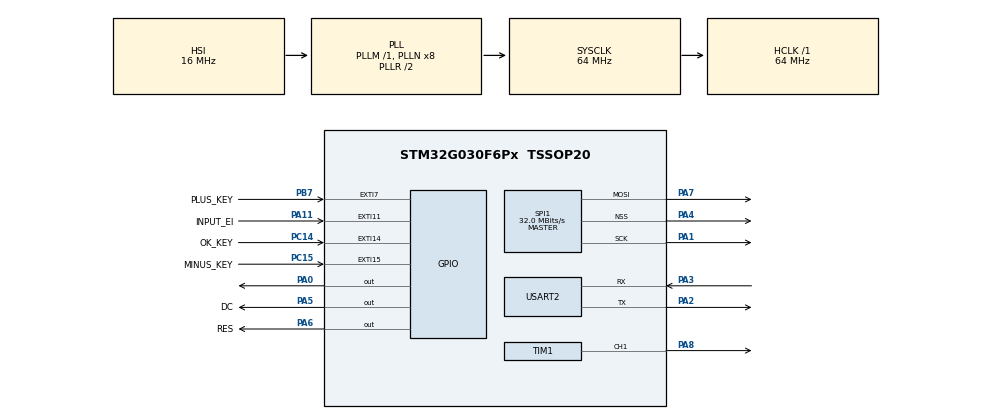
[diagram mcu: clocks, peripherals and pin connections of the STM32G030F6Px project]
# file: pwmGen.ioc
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Dma.Request0=SPI1_TX
Dma.Request1=USART2_TX
Dma.SPI1_TX.0.Direction=DMA_MEMORY_TO_PERIPH
Dma.SPI1_TX.0.EventEnable=DISABLE
Dma.SPI1_TX.0.Instance=DMA1_Channel1
Dma.SPI1_TX.0.MemDataAlignment=DMA_MDATAALIGN_BYTE
Dma.SPI1_TX.0.MemInc=DMA_MINC_ENABLE
Dma.SPI1_TX.0.Mode=DMA_NORMAL
Dma.SPI1_TX.0.PeriphDataAlignment=DMA_PDATAALIGN_BYTE
Dma.SPI1_TX.0.PeriphInc=DMA_PINC_DISABLE
Dma.SPI1_TX.0.Polarity=HAL_DMAMUX_REQ_GEN_RISING
Dma.SPI1_TX.0.Priority=DMA_PRIORITY_VERY_HIGH
Dma.SPI1_TX.0.RequestNumber=1
Dma.SPI1_TX.0.SignalID=NONE
Dma.SPI1_TX.0.SyncEnable=DISABLE
Dma.SPI1_TX.0.SyncPolarity=HAL_DMAMUX_SYNC_NO_EVENT
Dma.SPI1_TX.0.SyncRequestNumber=1
Dma.SPI1_TX.0.SyncSignalID=NONE
Dma.USART2_TX.1.Direction=DMA_MEMORY_TO_PERIPH
Dma.USART2_TX.1.EventEnable=DISABLE
Dma.USART2_TX.1.Instance=DMA1_Channel3
Dma.USART2_TX.1.MemDataAlignment=DMA_MDATAALIGN_BYTE
Dma.USART2_TX.1.MemInc=DMA_MINC_ENABLE
Dma.USART2_TX.1.Mode=DMA_NORMAL
Dma.USART2_TX.1.PeriphDataAlignment=DMA_PDATAALIGN_BYTE
Dma.USART2_TX.1.PeriphInc=DMA_PINC_DISABLE
Dma.USART2_TX.1.Polarity=HAL_DMAMUX_REQ_GEN_RISING
Dma.USART2_TX.1.Priority=DMA_PRIORITY_LOW
Dma.USART2_TX.1.RequestNumber=1
Dma.USART2_TX.1.SignalID=NONE
Dma.USART2_TX.1.SyncEnable=DISABLE
Dma.USART2_TX.1.SyncPolarity=HAL_DMAMUX_SYNC_NO_EVENT
Dma.USART2_TX.1.SyncRequestNumber=1
Dma.USART2_TX.1.SyncSignalID=NONE
FREERTOS.BinarySemaphores01=spiTranBinarySem,Dynamic,NULL;pageBinarySem,Dynamic,NULL;uartSendBinarySem,Dynamic,NULL
FREERTOS.Tasks01=guiTask,0,128,osGuiTask,Default,NULL,Dynamic,NULL,NULL;shellTask,-3,256,osShellTask,Default,NULL,Dynamic,NULL,NULL
FREERTOS.configTOTAL_HEAP_SIZE=3072
Mcu.Family=STM32G0
Mcu.Name=STM32G030F6Px
Mcu.Package=TSSOP20
NVIC.DMA1_Channel1_IRQn=true\:3\:0\:false\:false\:true\:true\:false\:true\:true
NVIC.DMA1_Channel2_3_IRQn=true\:3\:0\:false\:false\:true\:true\:false\:true\:true
NVIC.EXTI4_15_IRQn=true\:3\:0\:false\:false\:true\:true\:true\:true\:true
NVIC.SPI1_IRQn=true\:3\:0\:false\:false\:true\:true\:true\:true\:true
NVIC.TIM17_IRQn=true\:3\:0\:false\:false\:true\:false\:false\:true\:true
NVIC.TimeBase=TIM17_IRQn
NVIC.TimeBaseIP=TIM17
NVIC.USART2_IRQn=true\:3\:0\:false\:false\:true\:true\:true\:true\:true
PA0.Signal=GPIO_Output
PA1.GPIO_Speed=GPIO_SPEED_FREQ_VERY_HIGH
PA1.Mode=TX_Only_Simplex_Unidirect_Master
PA1.Signal=SPI1_SCK
PA11\ [PA9].GPIO_Label=INPUT_EI
PA11\ [PA9].GPIO_ModeDefaultEXTI=GPIO_MODE_IT_RISING_FALLING
PA11\ [PA9].Signal=GPXTI11
PA13.Mode=Serial_Wire
PA13.Signal=SYS_SWDIO
PA14-BOOT0.Mode=Serial_Wire
PA14-BOOT0.Signal=SYS_SWCLK
PA14-BOOT0__PA15.StandardMode=true
PA2.Mode=Asynchronous
PA2.Signal=USART2_TX
PA3.Mode=Asynchronous
PA3.Signal=USART2_RX
PA4.GPIO_Speed=GPIO_SPEED_FREQ_VERY_HIGH
PA4.Mode=NSS_Signal_Hard_Output
PA4.Signal=SPI1_NSS
PA5.GPIO_Label=DC
PA5.Signal=GPIO_Output
PA6.GPIO_Label=RES
PA6.GPIO_Speed=GPIO_SPEED_FREQ_VERY_HIGH
PA6.Signal=GPIO_Output
PA7.GPIO_Speed=GPIO_SPEED_FREQ_VERY_HIGH
PA7.Mode=TX_Only_Simplex_Unidirect_Master
PA7.Signal=SPI1_MOSI
PA8.GPIO_ModeDefaultPP=GPIO_MODE_AF_OD
PA8.GPIO_Speed=GPIO_SPEED_FREQ_VERY_HIGH
PA8.PinState=GPIO_PIN_SET
PA8.Signal=S_TIM1_CH1
PB0__PB1__PB2__PA8.StandardMode=true
PB3__PB4__PB5__PB6.StandardMode=true
PB7.GPIO_Label=PLUS_KEY
PB7.GPIO_ModeDefaultEXTI=GPIO_MODE_IT_RISING_FALLING
PB7.GPIO_PuPd=GPIO_NOPULL
PB7.Signal=GPXTI7
PB7__PB8.StandardMode=true
PC14-OSC32_IN\ (PC14).GPIO_Label=OK_KEY
PC14-OSC32_IN\ (PC14).GPIO_ModeDefaultEXTI=GPIO_MODE_IT_RISING_FALLING
PC14-OSC32_IN\ (PC14).GPIO_PuPd=GPIO_NOPULL
PC14-OSC32_IN\ (PC14).Signal=GPXTI14
PC14-OSC32_IN\ (PC14)__PB9.StandardMode=true
PC15-OSC32_OUT\ (PC15).GPIO_Label=MINUS_KEY
PC15-OSC32_OUT\ (PC15).GPIO_ModeDefaultEXTI=GPIO_MODE_IT_RISING_FALLING
PC15-OSC32_OUT\ (PC15).GPIO_PuPd=GPIO_NOPULL
PC15-OSC32_OUT\ (PC15).Signal=GPXTI15
ProjectManager.HeapSize=0x200
ProjectManager.StackSize=0x400
ProjectManager.TargetToolchain=MDK-ARM V5.32
RCC.ADCFreq_Value=64000000
RCC.AHBFreq_Value=64000000
RCC.CortexFreq_Value=64000000
RCC.EXTERNAL_CLOCK_VALUE=12288000
RCC.HCLKFreq_Value=64000000
RCC.HSE_VALUE=8000000
RCC.HSI_VALUE=16000000
RCC.LSE_VALUE=32768
RCC.SYSCLKFreq_VALUE=64000000
RCC.SYSCLKSource=RCC_SYSCLKSOURCE_PLLCLK
RCC.VCOOutputFreq_Value=128000000
SH.S_TIM1_CH1.0=TIM1_CH1,PWM Generation1 CH1
SPI1.BaudRatePrescaler=SPI_BAUDRATEPRESCALER_2
SPI1.CalculateBaudRate=32.0 MBits/s
SPI1.DataSize=SPI_DATASIZE_8BIT
SPI1.Direction=SPI_DIRECTION_2LINES
SPI1.Mode=SPI_MODE_MASTER
SPI1.VirtualNSS=VM_NSSHARD
SPI1.VirtualType=VM_MASTER
TIM1.Channel-PWM\ Generation1\ CH1=TIM_CHANNEL_1
USART2.VirtualMode-Asynchronous=VM_ASYNC
VP_FREERTOS_VS_CMSIS_V1.Mode=CMSIS_V1
VP_SYS_VS_tim17.Mode=TIM17
VP_TIM1_VS_ClockSourceINT.Mode=Internal
board=custom

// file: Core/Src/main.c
/* USER CODE BEGIN Header */
/**
  ******************************************************************************
  * @file           : main.c
  * @brief          : Main program body
  ******************************************************************************
  * @attention
  *
  * Copyright (c) 2024 STMicroelectronics.
  * All rights reserved.
  *
  * This software is licensed under terms that can be found in the LICENSE file
  * in the root directory of this software component.
  * If no LICENSE file comes with this software, it is provided AS-IS.
  *
  ******************************************************************************
  */
/* USER CODE END Header */
#include "main.h"
#include "cmsis_os.h"
#include "dma.h"
#include "spi.h"
#include "tim.h"
#include "usart.h"
#include "gpio.h"

void SystemClock_Config(void);
void MX_FREERTOS_Init(void);

int main(void)
{

  /* MCU Configuration--------------------------------------------------------*/

  /* Reset of all peripherals, Initializes the Flash interface and the Systick. */
  HAL_Init();

  /* Configure the system clock */
  SystemClock_Config();

  /* Initialize all configured peripherals */
  MX_GPIO_Init();
  MX_DMA_Init();
  MX_SPI1_Init();
  MX_TIM1_Init();
  MX_USART2_UART_Init();

  /* Call init function for freertos objects (in cmsis_os2.c) */
  MX_FREERTOS_Init();

  /* Start scheduler */
  osKernelStart();

  /* We should never get here as control is now taken by the scheduler */

  /* Infinite loop */
  while (1)
  {

  }
}

void SystemClock_Config(void)
{
  RCC_OscInitTypeDef RCC_OscInitStruct = {0};
  RCC_ClkInitTypeDef RCC_ClkInitStruct = {0};

  /** Configure the main internal regulator output voltage
  */
  HAL_PWREx_ControlVoltageScaling(PWR_REGULATOR_VOLTAGE_SCALE1);

  /** Initializes the RCC Oscillators according to the specified parameters
  * in the RCC_OscInitTypeDef structure.
  */
  RCC_OscInitStruct.OscillatorType = RCC_OSCILLATORTYPE_HSI;
  RCC_OscInitStruct.HSIState = RCC_HSI_ON;
  RCC_OscInitStruct.HSIDiv = RCC_HSI_DIV1;
  RCC_OscInitStruct.HSICalibrationValue = RCC_HSICALIBRATION_DEFAULT;
  RCC_OscInitStruct.PLL.PLLState = RCC_PLL_ON;
  RCC_OscInitStruct.PLL.PLLSource = RCC_PLLSOURCE_HSI;
  RCC_OscInitStruct.PLL.PLLM = RCC_PLLM_DIV1;
  RCC_OscInitStruct.PLL.PLLN = 8;
  RCC_OscInitStruct.PLL.PLLP = RCC_PLLP_DIV2;
  RCC_OscInitStruct.PLL.PLLR = RCC_PLLR_DIV2;
  if (HAL_RCC_OscConfig(&RCC_OscInitStruct) != HAL_OK)
  {
    Error_Handler();
  }

  /** Initializes the CPU, AHB and APB buses clocks
  */
  RCC_ClkInitStruct.ClockType = RCC_CLOCKTYPE_HCLK|RCC_CLOCKTYPE_SYSCLK
                              |RCC_CLOCKTYPE_PCLK1;
  RCC_ClkInitStruct.SYSCLKSource = RCC_SYSCLKSOURCE_PLLCLK;
  RCC_ClkInitStruct.AHBCLKDivider = RCC_SYSCLK_DIV1;
  RCC_ClkInitStruct.APB1CLKDivider = RCC_HCLK_DIV1;

  if (HAL_RCC_ClockConfig(&RCC_ClkInitStruct, FLASH_LATENCY_2) != HAL_OK)
  {
    Error_Handler();
  }
}

void HAL_TIM_PeriodElapsedCallback(TIM_HandleTypeDef *htim)
{
  if (htim->Instance == TIM17) {
    HAL_IncTick();
  }
}

void Error_Handler(void)
{
  __disable_irq();
  while (1)
  {
  }
}

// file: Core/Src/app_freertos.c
/* USER CODE BEGIN Header */
/**
  ******************************************************************************
  * File Name          : app_freertos.c
  * Description        : Code for freertos applications
  ******************************************************************************
  * @attention
  *
  * Copyright (c) 2024 STMicroelectronics.
  * All rights reserved.
  *
  * This software is licensed under terms that can be found in the LICENSE file
  * in the root directory of this software component.
  * If no LICENSE file comes with this software, it is provided AS-IS.
  *
  ******************************************************************************
  */
/* USER CODE END Header */

#include "FreeRTOS.h"
#include "task.h"
#include "main.h"
#include "cmsis_os.h"

/* USER CODE BEGIN Includes */
#include "userGui.h"
#include "u8g2.h"
#include "shell_port.h"
#include "shell.h"
/* USER CODE END Includes */

osThreadId guiTaskHandle;
osThreadId shellTaskHandle;
osSemaphoreId spiTranBinarySemHandle;
osSemaphoreId pageBinarySemHandle;
osSemaphoreId uartSendBinarySemHandle;

/* USER CODE BEGIN FunctionPrototypes */
extern SPI_HandleTypeDef hspi1;
/* USER CODE END FunctionPrototypes */

void osGuiTask(void const * argument);
void osShellTask(void const * argument);

void MX_FREERTOS_Init(void); /* (MISRA C 2004 rule 8.1) */

void MX_FREERTOS_Init(void) {

  /* Create the semaphores(s) */
  /* definition and creation of spiTranBinarySem */
  osSemaphoreDef(spiTranBinarySem);
  spiTranBinarySemHandle = osSemaphoreCreate(osSemaphore(spiTranBinarySem), 1);

  /* definition and creation of pageBinarySem */
  osSemaphoreDef(pageBinarySem);
  pageBinarySemHandle = osSemaphoreCreate(osSemaphore(pageBinarySem), 1);

  /* definition and creation of uartSendBinarySem */
  osSemaphoreDef(uartSendBinarySem);
  uartSendBinarySemHandle = osSemaphoreCreate(osSemaphore(uartSendBinarySem), 1);

  /* Create the thread(s) */
  /* definition and creation of guiTask */
  osThreadDef(guiTask, osGuiTask, osPriorityNormal, 0, 128);
  guiTaskHandle = osThreadCreate(osThread(guiTask), NULL);

  /* definition and creation of shellTask */
  osThreadDef(shellTask, osShellTask, osPriorityIdle, 0, 256);
  shellTaskHandle = osThreadCreate(osThread(shellTask), NULL);

}

void osGuiTask(void const * argument)
{
  /* USER CODE BEGIN osGuiTask */
  userGuiInit();
  /* Infinite loop */
  for(;;)
  {
		userGuiTask();
  }
  /* USER CODE END osGuiTask */
}

void osShellTask(void const * argument)
{
  /* USER CODE BEGIN osShellTask */
  /* Infinite loop */
	userShellInit();
  for(;;)
  {
		shellTask(&shell);
  }
  /* USER CODE END osShellTask */
}
